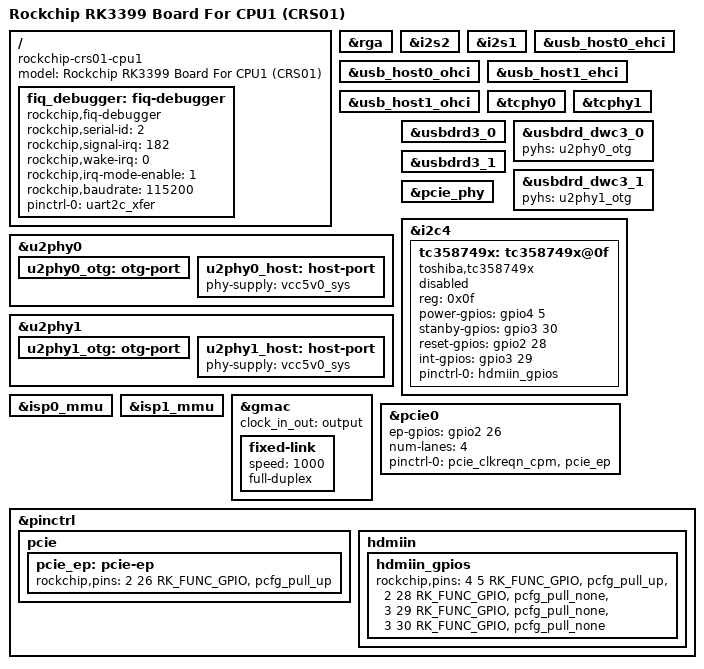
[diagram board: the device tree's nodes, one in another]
/*
 * Copyright (c) 2016 Fuzhou Rockchip Electronics Co., Ltd
 *
 * This file is dual-licensed: you can use it either under the terms
 * of the GPL or the X11 license, at your option. Note that this dual
 * licensing only applies to this file, and not this project as a
 * whole.
 *
 *  a) This file is free software; you can redistribute it and/or
 *     modify it under the terms of the GNU General Public License as
 *     published by the Free Software Foundation; either version 2 of the
 *     License, or (at your option) any later version.
 *
 *     This file is distributed in the hope that it will be useful,
 *     but WITHOUT ANY WARRANTY; without even the implied warranty of
 *     MERCHANTABILITY or FITNESS FOR A PARTICULAR PURPOSE.  See the
 *     GNU General Public License for more details.
 *
 * Or, alternatively,
 *
 *  b) Permission is hereby granted, free of charge, to any person
 *     obtaining a copy of this software and associated documentation
 *     files (the "Software"), to deal in the Software without
 *     restriction, including without limitation the rights to use,
 *     copy, modify, merge, publish, distribute, sublicense, and/or
 *     sell copies of the Software, and to permit persons to whom the
 *     Software is furnished to do so, subject to the following
 *     conditions:
 *
 *     The above copyright notice and this permission notice shall be
 *     included in all copies or substantial portions of the Software.
 *
 *     THE SOFTWARE IS PROVIDED "AS IS", WITHOUT WARRANTY OF ANY KIND,
 *     EXPRESS OR IMPLIED, INCLUDING BUT NOT LIMITED TO THE WARRANTIES
 *     OF MERCHANTABILITY, FITNESS FOR A PARTICULAR PURPOSE AND
 *     NONINFRINGEMENT. IN NO EVENT SHALL THE AUTHORS OR COPYRIGHT
 *     HOLDERS BE LIABLE FOR ANY CLAIM, DAMAGES OR OTHER LIABILITY,
 *     WHETHER IN AN ACTION OF CONTRACT, TORT OR OTHERWISE, ARISING
 *     FROM, OUT OF OR IN CONNECTION WITH THE SOFTWARE OR THE USE OR
 *     OTHER DEALINGS IN THE SOFTWARE.
 */

/dts-v1/;
#include "rk3399-crs01.dtsi"

/ {
	model = "Rockchip RK3399 Board For CPU1 (CRS01)";
	compatible = "rockchip-crs01-cpu1","rockchip,rk3399-crs01";
	fiq_debugger: fiq-debugger {
		compatible = "rockchip,fiq-debugger";
		rockchip,serial-id = <2>;
		rockchip,signal-irq = <182>;
		rockchip,wake-irq = <0>;
		rockchip,irq-mode-enable = <1>;  /* If enable uart uses irq instead of fiq */
		rockchip,baudrate = <1500000>;  /* Only 115200 and 1500000 */
		pinctrl-names = "default";
		pinctrl-0 = <&uart2c_xfer>;
	};
};
&rga{
	status="okay";
};

/* HDMI OUT sound */
&i2s2 {
	status = "okay";
};


/* External audio output */
&i2s1 {
	status = "okay";
};

/* USB2.0 Host * 2 */
&usb_host0_ehci {
	status = "okay";
};

&usb_host0_ohci {
	status = "okay";
};

&usb_host1_ehci {
	status = "okay";
};

&usb_host1_ohci {
	status = "okay";
};

&tcphy0 {
	//extcon = <&fusb0>;
	status = "okay";
};

&tcphy1 {
	status = "okay";
};

&u2phy0 {
        status = "okay";
        //extcon = <&fusb0>;

        u2phy0_otg: otg-port {
                status = "okay";
        };

        u2phy0_host: host-port {
                phy-supply = <&vcc5v0_sys>;
                status = "okay";
        };
};

&u2phy1 {
        status = "okay";

        u2phy1_otg: otg-port {
                status = "okay";
        };

        u2phy1_host: host-port {
                phy-supply = <&vcc5v0_sys>;
                status = "okay";
        };
};

&usbdrd3_0 {
        status = "okay";
};

&usbdrd_dwc3_0 {
	pyhs = <&u2phy0_otg>;
	phy-names = "usb2-phy";
        status = "okay";
};

&usbdrd3_1 {
        status = "okay";
};

&usbdrd_dwc3_1 {
	pyhs = <&u2phy1_otg>;
	phy-names = "usb2-phy";
        status = "okay";
};

/* PCIE SATA HD */
&pcie_phy {
	status = "okay";
};

&i2c4 {
	status = "okay";
	tc358749x: tc358749x@0f {
		compatible = "toshiba,tc358749x";
		reg = <0x0f>;
		power-gpios = <&gpio4 5 GPIO_ACTIVE_HIGH>;
		stanby-gpios = <&gpio3 30 GPIO_ACTIVE_HIGH>;
		reset-gpios = <&gpio2  28 GPIO_ACTIVE_HIGH>;
		int-gpios = <&gpio3 29 GPIO_ACTIVE_HIGH>;
		pinctrl-names = "default";
		pinctrl-0 = <&hdmiin_gpios>;
		status = "disabled";
	};

};


&isp0_mmu {
	status = "okay";
};


&isp1_mmu {
	status = "okay";
};

&gmac {
	clock_in_out = "output";
	phy-names = "marvell6176";
	status = "okay";
	fixed-link {
		speed = <1000>;
		full-duplex;
	};
};

&pcie0 {
	ep-gpios = <&gpio2 26 GPIO_ACTIVE_HIGH>;
	num-lanes = <4>;
	pinctrl-names = "default";
	pinctrl-0 = <&pcie_clkreqn_cpm &pcie_ep>;
	status = "okay";
};

&fiq_debugger {
	rockchip,baudrate = <115200>;
};

&pinctrl {
	pcie {
		pcie_ep: pcie-ep {
			rockchip,pins = <2 26 RK_FUNC_GPIO &pcfg_pull_up>;
		};
	};
	hdmiin {
		hdmiin_gpios: hdmiin_gpios {
			rockchip,pins =
				<4 5 RK_FUNC_GPIO &pcfg_pull_up>,
				<2 28 RK_FUNC_GPIO &pcfg_pull_none>,
				<3 29 RK_FUNC_GPIO &pcfg_pull_none>,
				<3 30 RK_FUNC_GPIO &pcfg_pull_none>;
		};
	};
};
